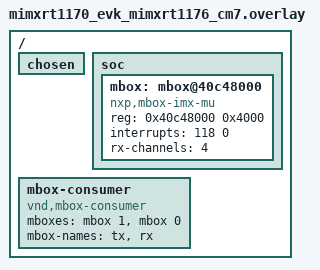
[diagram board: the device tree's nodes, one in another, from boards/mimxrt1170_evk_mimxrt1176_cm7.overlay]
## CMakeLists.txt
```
#
# Copyright 2023-2026 NXP
#
# SPDX-License-Identifier: BSD-3-Clause
#

cmake_minimum_required(VERSION 3.20.0)

find_package(Zephyr REQUIRED HINTS $ENV{ZEPHYR_BASE})

set(REMOTE_ZEPHYR_DIR ${CMAKE_CURRENT_BINARY_DIR}/../remote/zephyr)

if(("${BOARD}" STREQUAL "mimxrt1170_evkb") OR
   ("${BOARD}" STREQUAL "mimxrt1170_evk") OR
   ("${BOARD}" STREQUAL "mimxrt685_evk") OR
   ("${BOARD}" STREQUAL "mimxrt700_evk") OR
   ("${BOARD}" STREQUAL "mimxrt1160_evk"))
  message(STATUS "${BOARD} compile as Main in this sample")
else()
  message(FATAL_ERROR "${BOARD} is not supported for this sample")
endif()

project(matrix_multiply_mbox)

enable_language(C CXX)

if(CONFIG_INCLUDE_REMOTE_DIR)
  target_include_directories(zephyr_interface
    INTERFACE ${REMOTE_ZEPHYR_DIR}/include/public)
endif()

target_include_directories(app PRIVATE
    ${PROJECT_SOURCE_DIR}/
    ${PROJECT_SOURCE_DIR}/src
    ${PROJECT_SOURCE_DIR}/src/service
)

target_sources(app PRIVATE
    ${PROJECT_SOURCE_DIR}/src/main.cpp
    ${PROJECT_SOURCE_DIR}/src/erpc_error_handler.cpp

    # Generated shim code
    ${PROJECT_SOURCE_DIR}/src/service/c_erpc_matrix_multiply_client.cpp
    ${PROJECT_SOURCE_DIR}/src/service/erpc_matrix_multiply_client.cpp
    ${PROJECT_SOURCE_DIR}/src/service/erpc_matrix_multiply_interface.cpp
)

# Same for erpc library and erpc_config.h
target_include_directories(erpc PRIVATE ${CMAKE_CURRENT_SOURCE_DIR})

if (CONFIG_BOARD_MIMXRT685_EVK OR CONFIG_BOARD_MIMXRT700_EVK)
    include("${ZEPHYR_BASE}/samples/boards/nxp/adsp/rtxxx/common/dsp-load.cmake")
endif()
```

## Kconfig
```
#
# Copyright 2023-2024 NXP
#
# SPDX-License-Identifier: BSD-3-Clause
#

source "Kconfig.zephyr"

config INCLUDE_REMOTE_DIR
	bool "Include remote core header directory"
	help
	  Include remote build header files. Can be used if primary image
	  needs to be aware of size or base address of secondary image
```

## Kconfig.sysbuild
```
#
# Copyright 2023-2026 NXP
#
# SPDX-License-Identifier: BSD-3-Clause
#

source "share/sysbuild/Kconfig"

config REMOTE_BOARD
string
    default "mimxrt1170_evk/mimxrt1176/cm4" if $(BOARD) = "mimxrt1170_evk"
	default "mimxrt1160_evk/mimxrt1166/cm4" if $(BOARD) = "mimxrt1160_evk"
	default "mimxrt1170_evkb/mimxrt1176/cm4" if $(BOARD) = "mimxrt1170_evkb"
	default "mimxrt685_evk/mimxrt685s/hifi4" if $(BOARD) = "mimxrt685_evk"
	default "mimxrt700_evk/mimxrt798s/hifi4" if $(BOARD) = "mimxrt700_evk"
```

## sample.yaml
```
sample:
  description: eRPC Matrix multiplication using MBOX transport layer
  name: eRPC MBOX Matrix multiplication
common:
  sysbuild: true
  tags: mbox
```

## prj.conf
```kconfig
# C++ Language Support
CONFIG_CPP=y
CONFIG_STD_CPP20=y
CONFIG_NEWLIB_LIBC=y
CONFIG_GLIBCXX_LIBCPP=y

# Compiler
CONFIG_MAIN_STACK_SIZE=4096
CONFIG_HEAP_MEM_POOL_SIZE=8192
CONFIG_NO_OPTIMIZATIONS=y

# eRPC
CONFIG_ERPC=y
CONFIG_ERPC_TRANSPORT_MBOX=y

# MBOX
CONFIG_MBOX=y
```

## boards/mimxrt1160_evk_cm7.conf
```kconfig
CONFIG_MBOX_NXP_IMX_MU=y
CONFIG_INCLUDE_REMOTE_DIR=y
CONFIG_SECOND_CORE_MCUX=y
```

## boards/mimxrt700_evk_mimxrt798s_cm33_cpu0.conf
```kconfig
#
# Copyright 2026 NXP
#
# SPDX-License-Identifier: Apache-2.0
#
```

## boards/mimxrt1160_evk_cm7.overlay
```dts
/*
 * Copyright 2023-2024 NXP
 *
 * SPDX-License-Identifier: BSD-3-Clause
 */

/ {
	chosen {
		/* Delete ipc chosen property where old IPM mailbox driver bellow is
		 * configured.
		 */
		/delete-property/ zephyr,ipc;
	};

	soc {
		/* Delete IPM Driver node nxp,imx-mu */
		/delete-node/ mailbox@40c48000;

		/* Attach MBOX driver to MU Unit */
		mbox:mbox@40c48000 {
			compatible = "nxp,mbox-imx-mu";
			reg = <0x40c48000 0x4000>;
			interrupts = <118 0>;
			rx-channels = <4>;
			#mbox-cells = <1>;
			status = "okay";
		};
	};
};
```

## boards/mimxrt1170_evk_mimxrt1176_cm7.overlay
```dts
/*
 * Copyright 2023-2024 NXP
 *
 * SPDX-License-Identifier: BSD-3-Clause
 */

/ {
	chosen {
		/* Delete ipc chosen property where old IPM mailbox driver bellow is
		 * configured.
		 */
		/delete-property/ zephyr,ipc;
	};

	soc {
		/* Delete IPM Driver node nxp,imx-mu */
		/delete-node/ mailbox@40c48000;

		/* Attach MBOX driver to MU Unit */
		mbox:mbox@40c48000 {
			compatible = "nxp,mbox-imx-mu";
			reg = <0x40c48000 0x4000>;
			interrupts = <118 0>;
			rx-channels = <4>;
			#mbox-cells = <1>;
			status = "okay";
		};
	};

	mbox-consumer {
		compatible = "vnd,mbox-consumer";
		mboxes = <&mbox 1>, <&mbox 0>;
		mbox-names = "tx", "rx";
	};
};
```

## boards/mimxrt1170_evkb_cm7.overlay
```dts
/*
 * Copyright 2023-2024 NXP
 *
 * SPDX-License-Identifier: BSD-3-Clause
 */

/ {
	chosen {
		/* Delete ipc chosen property where old IPM mailbox driver bellow is
		 * configured.
		 */
		/delete-property/ zephyr,ipc;
	};

	soc {
		/* Delete IPM Driver node nxp,imx-mu */
		/delete-node/ mailbox@40c48000;

		/* Attach MBOX driver to MU Unit */
		mbox:mbox@40c48000 {
			compatible = "nxp,mbox-imx-mu";
			reg = <0x40c48000 0x4000>;
			interrupts = <118 0>;
			rx-channels = <4>;
			#mbox-cells = <1>;
			status = "okay";
		};
	};
};
```

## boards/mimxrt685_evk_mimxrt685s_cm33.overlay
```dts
/*
 * Copyright 2026 NXP
 *
 * SPDX-License-Identifier: Apache-2.0
 */

#include <zephyr/dt-bindings/ipc_service/static_vrings.h>
#include <zephyr/dt-bindings/memory-attr/memory-attr-arm.h>

#include <nxp/nxp_rt6xx_hifi4memsplit.dtsi>

&dsp {
	status = "okay";
};

/ {
	mbox-consumer {
		compatible = "vnd,mbox-consumer";
		mboxes = <&mbox 1>, <&mbox 0>;
		mbox-names = "tx", "rx";
	};
};
```

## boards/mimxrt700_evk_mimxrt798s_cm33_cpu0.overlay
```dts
/*
 * Copyright 2026 NXP
 *
 * SPDX-License-Identifier: Apache-2.0
 */

#include <zephyr/dt-bindings/ipc_service/static_vrings.h>
#include <zephyr/dt-bindings/memory-attr/memory-attr-arm.h>

#include <nxp/nxp_rt6xx_hifi4memsplit.dtsi>

&dsp {
	status = "okay";
};

/ {
	mbox-consumer {
		compatible = "vnd,mbox-consumer";
		mboxes = <&mbox4_a 1>, <&mbox4_a 0>;
		mbox-names = "tx", "rx";
	};
};

mbox: &mbox4_a {

};
```

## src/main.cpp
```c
/*
 * Copyright 2023-2026 NXP
 *
 * SPDX-License-Identifier: BSD-3-Clause
 */
#include <zephyr/kernel.h>
#include <zephyr/drivers/mbox.h>

#include "erpc_client_setup.h"
#include "erpc_mbox_zephyr_transport.hpp"
#include "erpc_error_handler.h"

#include "c_erpc_matrix_multiply_client.h"
#include "erpc_matrix_multiply_common.h"

#if defined(CONFIG_BOARD_MIMXRT685_EVK) || defined(CONFIG_BOARD_MIMXRT700_EVK)
#include "dsp.h"
#endif

/*******************************************************************************
 * Definitions
 ******************************************************************************/
#define MATRIX_ITEM_MAX_VALUE (50)
#define APP_ERPC_READY_EVENT_DATA (1U)

#define TX_ID (1)
#define RX_ID (0)

/*******************************************************************************
 * Variables
 ******************************************************************************/
extern bool g_erpc_error_occurred;

/*******************************************************************************
 * Prototypes
 ******************************************************************************/

/*******************************************************************************
 * Code
 ******************************************************************************/

/*!
 * @brief Fill matrices by random values
 */
static void fill_matrices(Matrix matrix1_ptr, Matrix matrix2_ptr)
{
    int32_t a, b;

    /* Fill both matrices by random values */
    for (a = 0; a < matrix_size; ++a)
    {
        for (b = 0; b < matrix_size; ++b)
        {
            matrix1_ptr[a][b] = rand() % MATRIX_ITEM_MAX_VALUE;
            matrix2_ptr[a][b] = rand() % MATRIX_ITEM_MAX_VALUE;
        }
    }
}

/*!
 * @brief Printing a matrix to the console
 */
static void print_matrix(Matrix matrix_ptr)
{
    int32_t a, b;

    for (a = 0; a < matrix_size; ++a)
    {
        for (b = 0; b < matrix_size; ++b)
        {
            printk("%4i ", matrix_ptr[a][b]);
        }
        printk("\r\n");
    }
}

int main(void)
{
    const struct mbox_dt_spec rx_channel = MBOX_DT_SPEC_GET(DT_PATH(mbox_consumer), rx);
    const struct mbox_dt_spec tx_channel = MBOX_DT_SPEC_GET(DT_PATH(mbox_consumer), tx);
    const struct device *dev;

    erpc_transport_t transport;
    erpc_client_t client;

    Matrix matrix1 = { 0 }, matrix2 = { 0 }, result_matrix = { 0 };

#if defined(CONFIG_BOARD_MIMXRT685_EVK) || defined(CONFIG_BOARD_MIMXRT700_EVK)
    dsp_start();
    k_sleep(K_MSEC(500));
#endif

    dev = DEVICE_DT_GET(DT_NODELABEL(mbox));

    transport = erpc_transport_zephyr_mbox_init((void *)dev, (void *)&tx_channel, (void *)&rx_channel);

    /* MessageBufferFactory initialization */
    erpc_mbf_t message_buffer_factory;
    message_buffer_factory = erpc_mbf_dynamic_init();

    /* eRPC client side initialization */
    client = erpc_client_init(transport, message_buffer_factory);
    initMatrixMultiplyService_client(client);

    /* Set default error handler */
    erpc_client_set_error_handler(client, erpc_error_handler);

    /* Fill both matrices by random values */
    fill_matrices(matrix1, matrix2);

    /* Print both matrices on the console */
    printk("\r\nMatrix #1");
    printk("\r\n=========\r\n");
    print_matrix(matrix1);

    printk("\r\nMatrix #2");
    printk("\r\n=========\r\n");
    print_matrix(matrix2);

    for (;;)
    {
        printk("\r\neRPC request is sent to the server\r\n");

        erpcMatrixMultiply(matrix1, matrix2, result_matrix);

        /* Check if some error occurred in eRPC */
        if (g_erpc_error_occurred)
        {
            /* Exit program loop */
            break;
        }

        printk("\r\nResult matrix");
        printk("\r\n=============\r\n");
        print_matrix(result_matrix);

        k_sleep(K_MSEC(1000));

        /* Fill both matrices by random values */
        fill_matrices(matrix1, matrix2);

        /* Print both matrices on the console */
        printk("\r\nMatrix #1");
        printk("\r\n=========\r\n");
        print_matrix(matrix1);

        printk("\r\nMatrix #2");
        printk("\r\n=========\r\n");
        print_matrix(matrix2);
    }
    for (;;)
    {
    }
}
```
